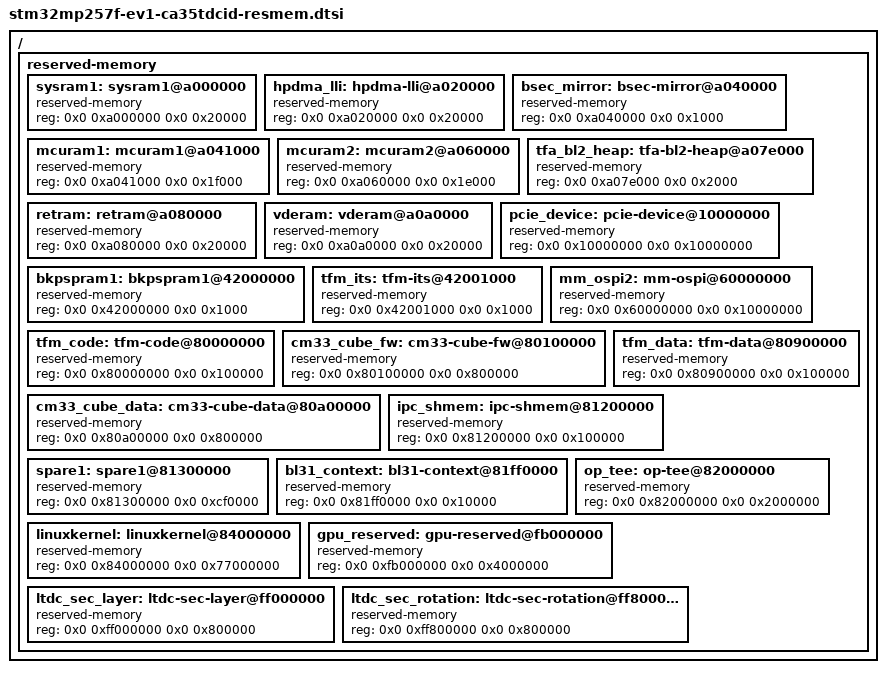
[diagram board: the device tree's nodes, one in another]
// SPDX-License-Identifier: (GPL-2.0-only OR BSD-3-Clause)
/*
 * Copyright (C) STMicroelectronics 2023 - All Rights Reserved
 */

/*
 * STM32MP25 reserved memory device tree configuration
 * Project : open
 * Generated by XLmx tool version 2.2 - 7/4/2023 9:06:24 AM
 */

/ {
	reserved-memory {
		#address-cells = <2>;
		#size-cells = <2>;
		ranges;

		/* Internal RAM reserved memory declaration */
		sysram1: sysram1@a000000 {
			compatible = "reserved-memory";
			reg = <0x0 0xa000000 0x0 0x20000>;
			#memory-region-cells = <0>;
		};

		hpdma_lli: hpdma-lli@a020000 {
			compatible = "reserved-memory";
			reg = <0x0 0xa020000 0x0 0x20000>;
			#memory-region-cells = <0>;
		};

		bsec_mirror: bsec-mirror@a040000 {
			compatible = "reserved-memory";
			reg = <0x0 0xa040000 0x0 0x1000>;
			#memory-region-cells = <0>;
		};

		mcuram1: mcuram1@a041000 {
			compatible = "reserved-memory";
			reg = <0x0 0xa041000 0x0 0x1f000>;
			#memory-region-cells = <0>;
		};

		mcuram2: mcuram2@a060000 {
			compatible = "reserved-memory";
			reg = <0x0 0xa060000 0x0 0x1e000>;
			#memory-region-cells = <0>;
		};

		tfa_bl2_heap: tfa-bl2-heap@a07e000 {
			compatible = "reserved-memory";
			reg = <0x0 0xa07e000 0x0 0x2000>;
			#memory-region-cells = <0>;
		};

		retram: retram@a080000 {
			compatible = "reserved-memory";
			reg = <0x0 0xa080000 0x0 0x20000>;
			#memory-region-cells = <0>;
		};

		vderam: vderam@a0a0000 {
			compatible = "reserved-memory";
			reg = <0x0 0xa0a0000 0x0 0x20000>;
			#memory-region-cells = <0>;
		};

		/* PCIe reserved memory declaration */
		pcie_device: pcie-device@10000000 {
			compatible = "reserved-memory";
			reg = <0x0 0x10000000 0x0 0x10000000>;
			#memory-region-cells = <0>;
		};

		/* Backup RAM reserved memory declaration */
		bkpspram1: bkpspram1@42000000 {
			compatible = "reserved-memory";
			reg = <0x0 0x42000000 0x0 0x1000>;
			#memory-region-cells = <0>;
		};

		tfm_its: tfm-its@42001000 {
			compatible = "reserved-memory";
			reg = <0x0 0x42001000 0x0 0x1000>;
			#memory-region-cells = <0>;
		};

		/* Octo Memory Manager reserved memory declaration */
		mm_ospi2: mm-ospi@60000000 {
			compatible = "reserved-memory";
			reg = <0x0 0x60000000 0x0 0x10000000>;
			#memory-region-cells = <0>;
		};

		/* DDR reserved memory declaration */
		tfm_code: tfm-code@80000000 {
			compatible = "reserved-memory";
			reg = <0x0 0x80000000 0x0 0x100000>;
			#memory-region-cells = <0>;
		};

		cm33_cube_fw: cm33-cube-fw@80100000 {
			compatible = "reserved-memory";
			reg = <0x0 0x80100000 0x0 0x800000>;
			#memory-region-cells = <0>;
		};

		tfm_data: tfm-data@80900000 {
			compatible = "reserved-memory";
			reg = <0x0 0x80900000 0x0 0x100000>;
			#memory-region-cells = <0>;
		};

		cm33_cube_data: cm33-cube-data@80a00000 {
			compatible = "reserved-memory";
			reg = <0x0 0x80a00000 0x0 0x800000>;
			#memory-region-cells = <0>;
		};

		ipc_shmem: ipc-shmem@81200000 {
			compatible = "reserved-memory";
			reg = <0x0 0x81200000 0x0 0x100000>;
			#memory-region-cells = <0>;
		};

		spare1: spare1@81300000 {
			compatible = "reserved-memory";
			reg = <0x0 0x81300000 0x0 0xcf0000>;
			#memory-region-cells = <0>;
		};

		bl31_context: bl31-context@81ff0000 {
			compatible = "reserved-memory";
			reg = <0x0 0x81ff0000 0x0 0x10000>;
			#memory-region-cells = <0>;
		};

		op_tee: op-tee@82000000 {
			compatible = "reserved-memory";
			reg = <0x0 0x82000000 0x0 0x2000000>;
			#memory-region-cells = <0>;
		};

		linuxkernel: linuxkernel@84000000 {
			compatible = "reserved-memory";
			reg = <0x0 0x84000000 0x0 0x77000000>;
			#memory-region-cells = <0>;
		};

		gpu_reserved: gpu-reserved@fb000000 {
			compatible = "reserved-memory";
			reg = <0x0 0xfb000000 0x0 0x4000000>;
			#memory-region-cells = <0>;
		};

		ltdc_sec_layer: ltdc-sec-layer@ff000000 {
			compatible = "reserved-memory";
			reg = <0x0 0xff000000 0x0 0x800000>;
			#memory-region-cells = <0>;
		};

		ltdc_sec_rotation: ltdc-sec-rotation@ff800000 {
			compatible = "reserved-memory";
			reg = <0x0 0xff800000 0x0 0x800000>;
			#memory-region-cells = <0>;
		};

	};
};
